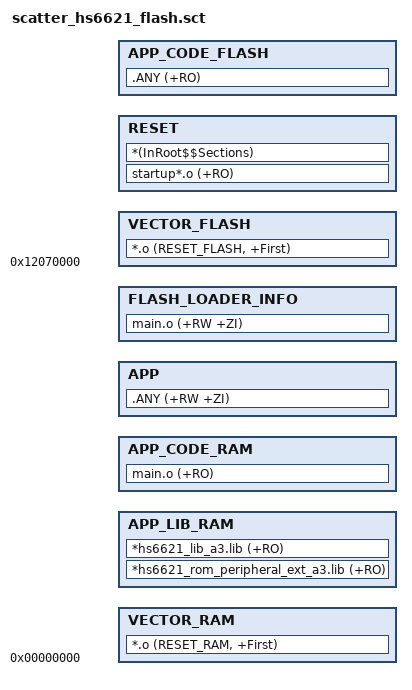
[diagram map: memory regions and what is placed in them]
#! armcc -E
; ***************************************************************
; *** Scatter-Loading Description File generated by Huntersun ***
; ***************************************************************

#define FLASH_LOADER_ADDR        0x12070000
#define FLASH_LOADER_SIZE_LIMIT  0x00006000


FLASH_LOAD FLASH_LOADER_ADDR (FLASH_LOADER_SIZE_LIMIT)
{
    ; Vector in Flash
    VECTOR_FLASH FLASH_LOADER_ADDR
    {
        *.o (RESET_FLASH, +First)
    }

    ; Startup and Keil Root code in Flash
    RESET +0
    {
        startup*.o (+RO)
        *(InRoot$$Sections)
    }

    ; Other Code in Flash
    APP_CODE_FLASH +0
    {
        .ANY (+RO)
    }

    ; Vector in RAM
    VECTOR_RAM 0
    {
        *.o (RESET_RAM, +First)
    }

    ; Critical library code in RAM
    APP_LIB_RAM +0
    {
        *hs6621_rom_peripheral_ext_a3.lib (+RO)
        *hs6621_lib_a3.lib (+RO)
    }

    ; User critical code in RAM
    APP_CODE_RAM +0
    {
        main.o (+RO)
    }

    ; Data in RAM
    APP 0x20000000 + ImageLimit(APP_CODE_RAM)
    {
        .ANY (+RW +ZI)
    }
    FLASH_LOADER_INFO AlignExpr(ImageLimit(APP), 4096)
    {
        main.o (+RW +ZI)
    }

}


